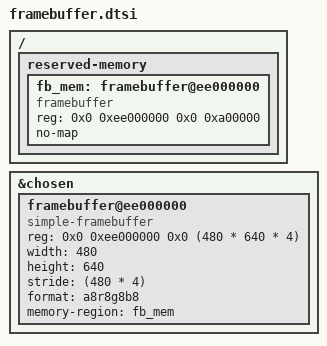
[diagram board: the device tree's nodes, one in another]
/ {
	reserved-memory {
		#address-cells = <2>;
		#size-cells = <2>;
		ranges;

		fb_mem: framebuffer@ee000000 {
			compatible = "framebuffer";
			reg = <0x0 0xee000000 0x0 0xa00000>;
			no-map;
		};
	};
};

&chosen {
	#address-cells = <2>;
	#size-cells = <2>;
	ranges;

	framebuffer@ee000000 {
		compatible = "simple-framebuffer";
		reg = <0x0 0xee000000 0x0 (480 * 640 * 4)>;
		width = <480>;
		height = <640>;
		stride = <(480 * 4)>;
		format = "a8r8g8b8";
		memory-region = <&fb_mem>;
	};
};
